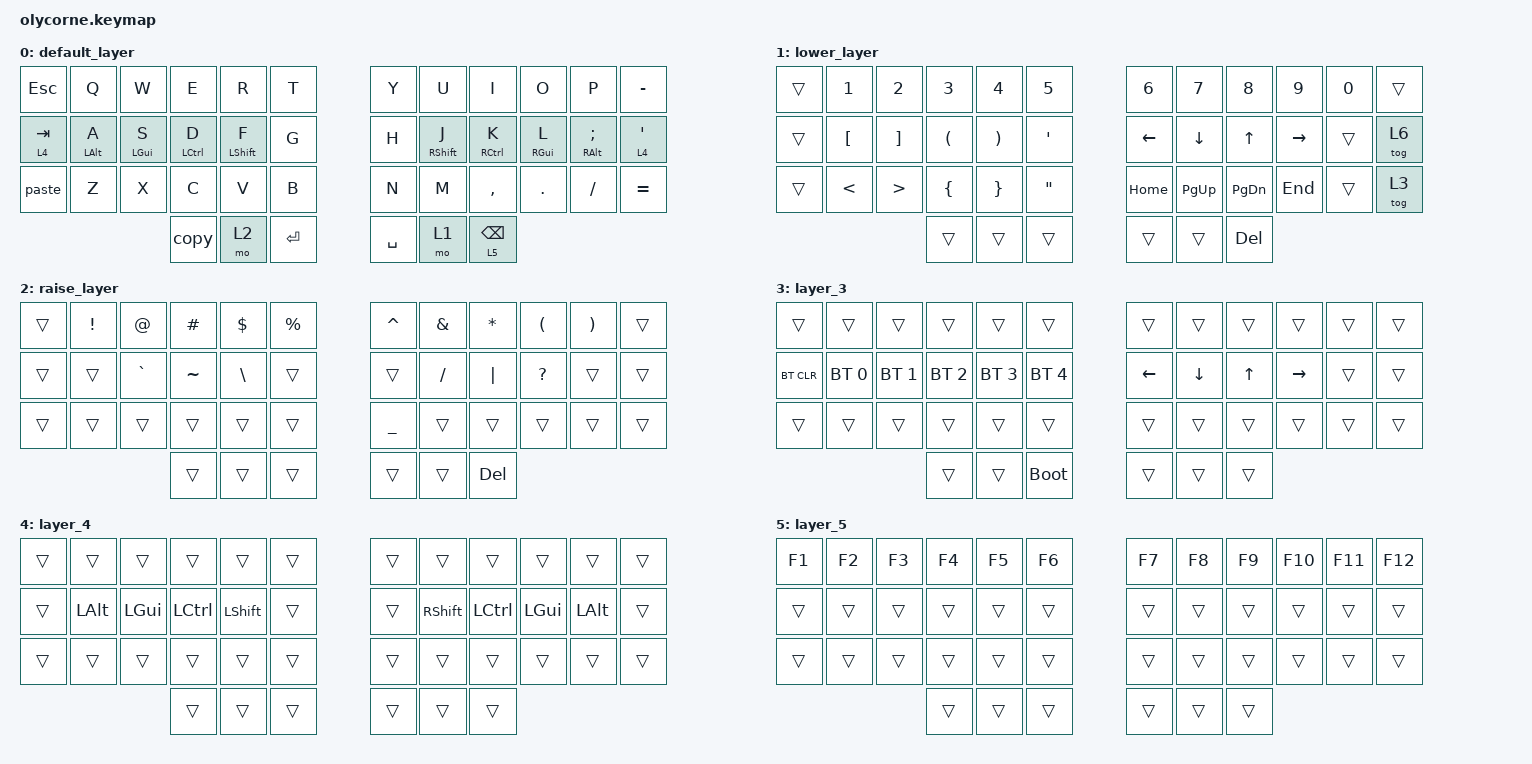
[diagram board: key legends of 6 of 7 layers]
/*
 * Copyright (c) 2020 The ZMK Contributors
 *
 * SPDX-License-Identifier: MIT
 */

#include <behaviors.dtsi>
#include <dt-bindings/zmk/bt.h>
#include <dt-bindings/zmk/keys.h>

&mt {
    retro-tap;
    tapping-term-ms = <400>;
};

/ {
    behaviors {
        lh_pht: left_positional_hold_tap {
            compatible = "zmk,behavior-hold-tap";
            #binding-cells = <2>;
            flavor = "balanced";
            tapping-term-ms = <400>;                        // <---[[produces tap if held longer than tapping-term-ms]]
            quick-tap-ms = <200>;
            bindings = <&kp>, <&kp>;

            hold-trigger-key-positions = <6 7 8 9 10 6 7 8 9 10 11 18 19 20 21 22 23 30 31 32 33 34 35 39 40 41 38>;    // <---[[right-hand keys]]
        };

        rh_pht: rh_pht {
            compatible = "zmk,behavior-hold-tap";
            #binding-cells = <2>;
            flavor = "balanced";
            tapping-term-ms = <400>;
            quick-tap-ms = <200>;
            bindings = <&kp>, <&kp>;

            label = "RH_PHT";
            hold-trigger-key-positions = <0 1 2 3 4 5 0 1 2 3 4 5 12 13 14 15 16 17 24 25 26 27 28 29 36 37 38>;
        };

        hypermod: hypermod {
            compatible = "zmk,behavior-hold-tap";
            #binding-cells = <2>;
            flavor = "hold-preferred";
            tapping-term-ms = <400>;
            quick-tap-ms = <200>;
            bindings = <&mo>, <&kp>;

            label = "HYPERMOD";
            hold-trigger-key-positions = <13 14 16 15 19 20 21 22>;
        };

        fmod: fmod {
            compatible = "zmk,behavior-hold-tap";
            #binding-cells = <2>;
            flavor = "tap-unless-interrupted";
            tapping-term-ms = <400>;
            quick-tap-ms = <200>;
            bindings = <&mo>, <&kp>;

            label = "FMOD";
            hold-trigger-key-positions = <0 1 2 3 4 5 6 7 8 9 10 11>;
        };

        copy: copy {
            compatible = "zmk,behavior-mod-morph";
            label = "COPY";
            bindings = <&ctrlmod C>, <&ctrlshiftmod C>;

            #binding-cells = <0>;
            mods = <(MOD_RSFT|MOD_LSFT)>;
        };

        paste: paste {
            compatible = "zmk,behavior-mod-morph";
            label = "PASTE";
            bindings = <&ctrlmod V>, <&ctrlshiftmod V>;

            #binding-cells = <0>;
            mods = <(MOD_RSFT|MOD_LSFT)>;
        };
    };

    macros {
        ctrlmod: cp {
            compatible = "zmk,behavior-macro-one-param";
            #binding-cells = <1>;
            bindings =
                <&macro_wait_time 50>,
                <&macro_press>,
                <&kp LCTRL>,
                <&macro_tap>,
                <&macro_param_1to1 &kp MACRO_PLACEHOLDER>,
                <&macro_release>,
                <&kp LCTRL>;

            label = "CP";
        };

        ctrlshiftmod: ctrlshiftmod {
            compatible = "zmk,behavior-macro-one-param";
            #binding-cells = <1>;
            bindings =
                <&macro_wait_time 55>,
                <&macro_release>,
                <&kp RIGHT_SHIFT>,
                <&macro_press>,
                <&kp LCTRL &kp LEFT_SHIFT>,
                <&macro_tap>,
                <&macro_param_1to1 &kp MACRO_PLACEHOLDER>,
                <&macro_release>,
                <&kp LEFT_SHIFT &kp LCTRL>;

            label = "CTRLSHIFTMOD";
        };
    };

    keymap {
        compatible = "zmk,keymap";

        default_layer {
            // -----------------------------------------------------------------------------------------
            // |  TAB |  Q  |  W  |  E  |  R  |  T  |   |  Y  |  U   |  I  |  O  |  P  | BKSP |
            // | CTRL |  A  |  S  |  D  |  F  |  G  |   |  H  |  J   |  K  |  L  |  ;  |  '   |
            // | SHFT |  Z  |  X  |  C  |  V  |  B  |   |  N  |  M   |  ,  |  .  |  /  | ESC  |
            //                    | GUI | LWR | SPC |   | ENT | RSE  | ALT |

            bindings = <
&kp ESCAPE       &kp Q               &kp W               &kp E            &kp R                 &kp T      &kp Y      &kp U                  &kp I              &kp O                &kp P                   &kp MINUS
&hypermod 4 TAB  &lh_pht LEFT_ALT A  &lh_pht LEFT_GUI S  &lh_pht LCTRL D  &lh_pht LEFT_SHIFT F  &kp G      &kp H      &rh_pht RIGHT_SHIFT J  &rh_pht RCTRL K    &rh_pht RIGHT_GUI L  &rh_pht RIGHT_ALT SEMI  &hypermod 4 APOS
&paste           &kp Z               &kp X               &kp C            &kp V                 &kp B      &kp N      &kp M                  &kp COMMA          &kp DOT              &kp FSLH                &kp EQUAL
                                                         &copy            &mo 2                 &kp RET    &kp SPACE  &mo 1                  &fmod 5 BACKSPACE
            >;
        };

        lower_layer {
            // -----------------------------------------------------------------------------------------
            // |  TAB |  1  |  2  |  3  |  4  |  5  |   |  6  |  7  |  8  |  9  |  0  | BKSP |
            // | BTCLR| BT1 | BT2 | BT3 | BT4 | BT5 |   | LFT | DWN |  UP | RGT |     |      |
            // | SHFT |     |     |     |     |     |   |     |     |     |     |     |      |
            //                    | GUI |     | SPC |   | ENT |     | ALT |

            bindings = <
&trans  &kp N1            &kp N2             &kp N3                &kp N4                 &kp N5               &kp N6    &kp N7     &kp N8      &kp N9     &kp N0  &trans
&trans  &kp LEFT_BRACKET  &kp RIGHT_BRACKET  &kp LEFT_PARENTHESIS  &kp RIGHT_PARENTHESIS  &kp SQT              &kp LEFT  &kp DOWN   &kp UP      &kp RIGHT  &trans  &tog 6
&trans  &kp LESS_THAN     &kp GREATER_THAN   &kp LEFT_BRACE        &kp RIGHT_BRACE        &kp DOUBLE_QUOTES    &kp HOME  &kp PG_UP  &kp PG_DN   &kp END    &trans  &tog 3
                                             &trans                &trans                 &trans               &trans    &trans     &kp DELETE
            >;
        };

        raise_layer {
            // -----------------------------------------------------------------------------------------
            // |  TAB |  !  |  @  |  #  |  $  |  %  |   |  ^  |  &  |  *  |  (  |  )  | BKSP |
            // | CTRL |     |     |     |     |     |   |  -  |  =  |  [  |  ]  |  \  |  `   |
            // | SHFT |     |     |     |     |     |   |  _  |  +  |  {  |  }  | "|" |  ~   |
            //                    | GUI |     | SPC |   | ENT |     | ALT |

            bindings = <
&trans  &kp EXCL  &kp AT     &kp HASH   &kp DLLR       &kp PRCNT    &kp CARET       &kp AMPS   &kp ASTRK   &kp LPAR      &kp RPAR  &trans
&trans  &trans    &kp GRAVE  &kp TILDE  &kp BACKSLASH  &trans       &trans          &kp SLASH  &kp PIPE    &kp QUESTION  &trans    &trans
&trans  &trans    &trans     &trans     &trans         &trans       &kp UNDERSCORE  &trans     &trans      &trans        &trans    &trans
                             &trans     &trans         &trans       &trans          &trans     &kp DELETE
            >;
        };

        layer_3 {
            bindings = <
&trans      &trans        &trans        &trans        &trans        &trans          &trans    &trans    &trans  &trans     &trans  &trans
&bt BT_CLR  &bt BT_SEL 0  &bt BT_SEL 1  &bt BT_SEL 2  &bt BT_SEL 3  &bt BT_SEL 4    &kp LEFT  &kp DOWN  &kp UP  &kp RIGHT  &trans  &trans
&trans      &trans        &trans        &trans        &trans        &trans          &trans    &trans    &trans  &trans     &trans  &trans
                                        &trans        &trans        &bootloader     &trans    &trans    &trans
            >;
        };

        layer_4 {
            bindings = <
&trans  &trans    &trans    &trans     &trans     &trans    &trans  &trans     &trans     &trans    &trans    &trans
&trans  &kp LALT  &kp LGUI  &kp LCTRL  &kp LSHFT  &trans    &trans  &kp RSHFT  &kp LCTRL  &kp LGUI  &kp LALT  &trans
&trans  &trans    &trans    &trans     &trans     &trans    &trans  &trans     &trans     &trans    &trans    &trans
                            &trans     &trans     &trans    &trans  &trans     &trans
            >;
        };

        layer_5 {
            bindings = <
&kp F1  &kp F2  &kp F3  &kp F4  &kp F5  &kp F6    &kp F7  &kp F8  &kp F9  &kp F10  &kp F11  &kp F12
&trans  &trans  &trans  &trans  &trans  &trans    &trans  &trans  &trans  &trans   &trans   &trans
&trans  &trans  &trans  &trans  &trans  &trans    &trans  &trans  &trans  &trans   &trans   &trans
                        &trans  &trans  &trans    &trans  &trans  &trans
            >;
        };

        layer_6 {
            bindings = <
&none  &none         &kp W         &none         &none         &none        &none  &none  &none  &none  &none  &none
&none  &kp A         &kp S         &kp D         &none         &none        &none  &none  &none  &none  &none  &tog 6
&none  &kp NUMBER_1  &kp NUMBER_2  &kp NUMBER_3  &kp NUMBER_4  &none        &none  &none  &none  &none  &none  &kp ESC
                                   &kp F5        &kp ESCAPE    &kp SPACE    &none  &none
            >;
        };
    };
};
